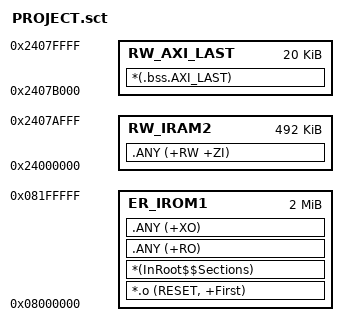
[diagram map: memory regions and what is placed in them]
; *************************************************************
; *** Scatter-Loading Description File generated by uVision ***
; *************************************************************

LR_IROM1 0x08000000 0x00200000  {    ; load region size_region
  ER_IROM1 0x08000000 0x00200000  {  ; load address = execution address
   *.o (RESET, +First)
   *(InRoot$$Sections)
   .ANY (+RO)
   .ANY (+XO)
  }
  RW_IRAM2 0x24000000 0x0007B000  {  ; RW data
   .ANY (+RW +ZI)
  }
  ; 新增：AXI SRAM最后专用区域用作内存管理
  RW_AXI_LAST 0x2407B000 0x00005000  {
   *(.bss.AXI_LAST)
  }
}
